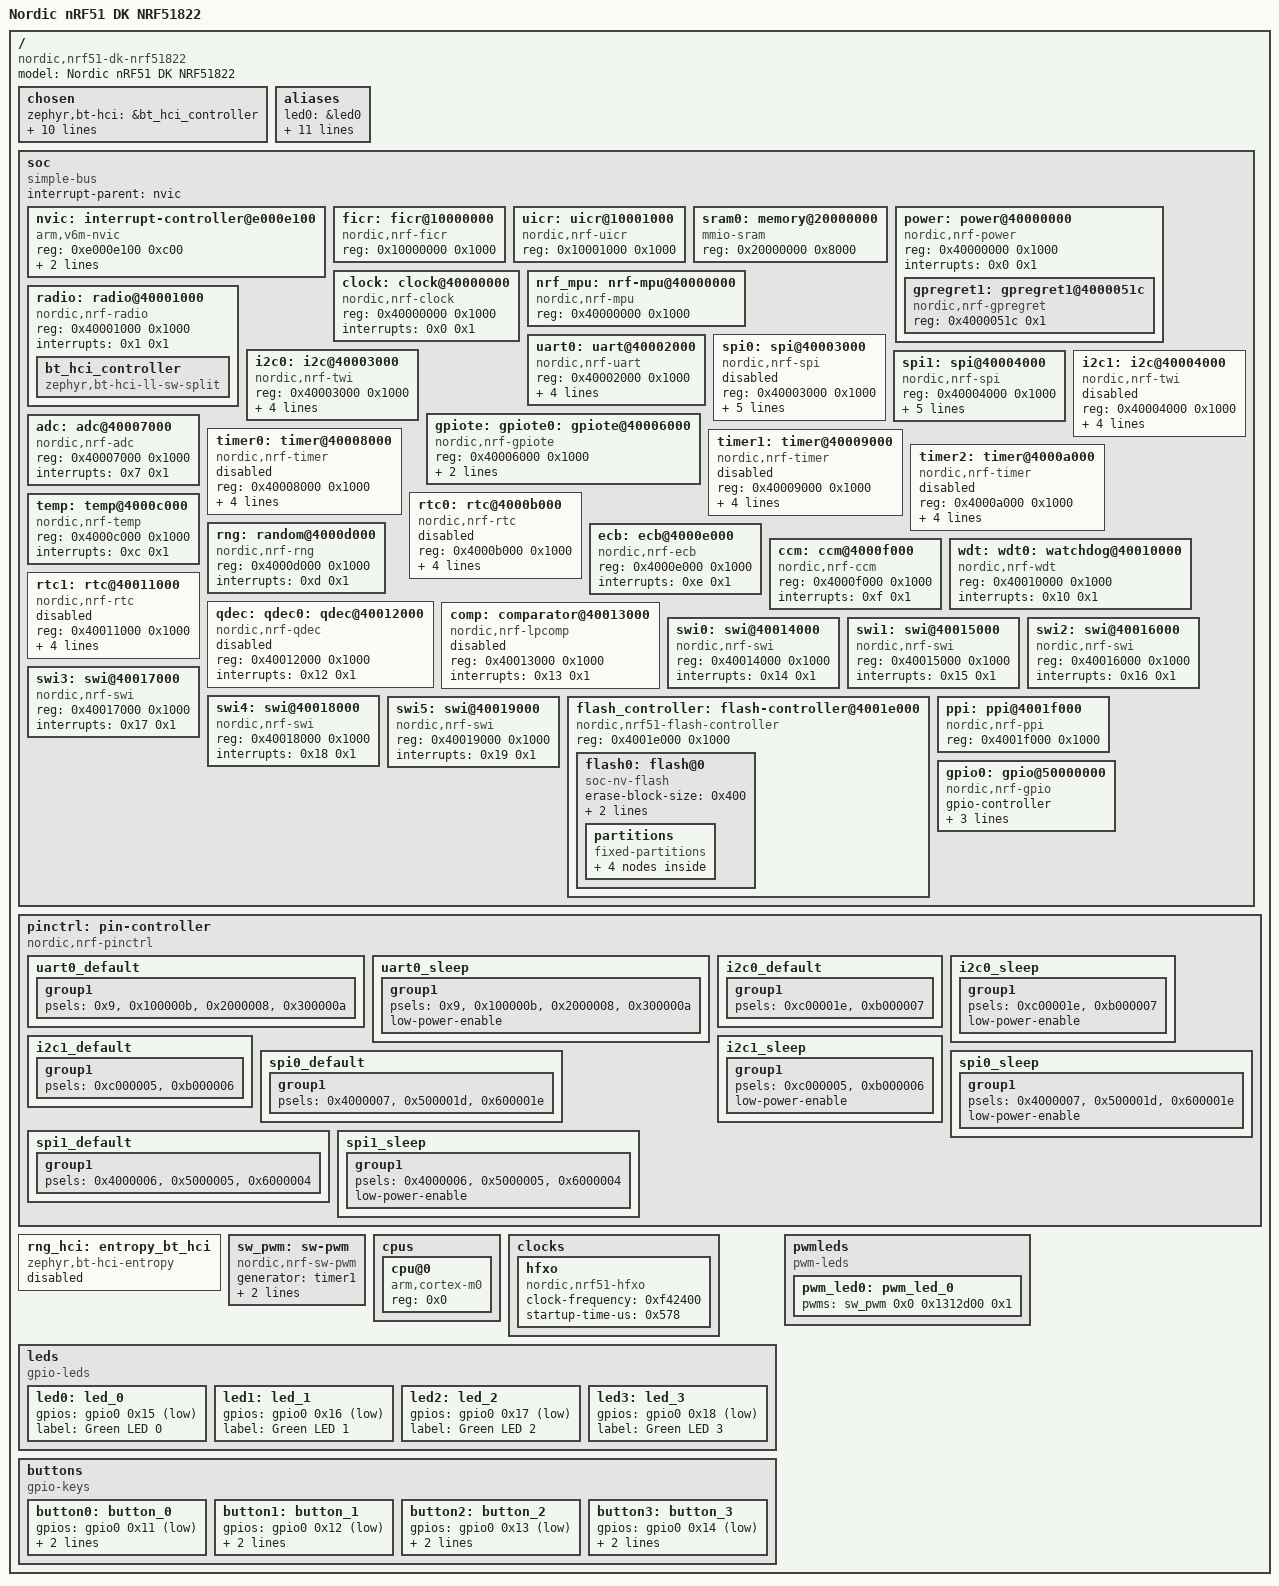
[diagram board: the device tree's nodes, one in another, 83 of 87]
/dts-v1/;

/* node '/' defined in zephyr/dts/common/skeleton.dtsi:9 */
/ {
	#address-cells = < 0x1 >;                /* in zephyr/dts/common/skeleton.dtsi:10 */
	#size-cells = < 0x1 >;                   /* in zephyr/dts/common/skeleton.dtsi:11 */
	model = "Nordic nRF51 DK NRF51822";      /* in zephyr/boards/nordic/nrf51dk/nrf51dk_nrf51822.dts:13 */
	compatible = "nordic,nrf51-dk-nrf51822"; /* in zephyr/boards/nordic/nrf51dk/nrf51dk_nrf51822.dts:14 */

	/* node '/chosen' defined in zephyr/dts/common/skeleton.dtsi:13 */
	chosen {
		zephyr,bt-hci = &bt_hci_controller;          /* in zephyr/dts/arm/nordic/nrf51822.dtsi:9 */
		zephyr,entropy = &rng;                       /* in zephyr/dts/arm/nordic/nrf51822.dtsi:10 */
		zephyr,flash-controller = &flash_controller; /* in zephyr/dts/arm/nordic/nrf51822.dtsi:11 */
		zephyr,console = &uart0;                     /* in zephyr/boards/nordic/nrf51dk/nrf51dk_nrf51822.dts:17 */
		zephyr,shell-uart = &uart0;                  /* in zephyr/boards/nordic/nrf51dk/nrf51dk_nrf51822.dts:18 */
		zephyr,uart-mcumgr = &uart0;                 /* in zephyr/boards/nordic/nrf51dk/nrf51dk_nrf51822.dts:19 */
		zephyr,bt-mon-uart = &uart0;                 /* in zephyr/boards/nordic/nrf51dk/nrf51dk_nrf51822.dts:20 */
		zephyr,bt-c2h-uart = &uart0;                 /* in zephyr/boards/nordic/nrf51dk/nrf51dk_nrf51822.dts:21 */
		zephyr,sram = &sram0;                        /* in zephyr/boards/nordic/nrf51dk/nrf51dk_nrf51822.dts:22 */
		zephyr,flash = &flash0;                      /* in zephyr/boards/nordic/nrf51dk/nrf51dk_nrf51822.dts:23 */
		zephyr,code-partition = &slot0_partition;    /* in zephyr/boards/nordic/nrf51dk/nrf51dk_nrf51822.dts:24 */
	};

	/* node '/aliases' defined in zephyr/dts/common/skeleton.dtsi:15 */
	aliases {
		led0 = &led0;               /* in zephyr/boards/nordic/nrf51dk/nrf51dk_nrf51822.dts:89 */
		led1 = &led1;               /* in zephyr/boards/nordic/nrf51dk/nrf51dk_nrf51822.dts:90 */
		led2 = &led2;               /* in zephyr/boards/nordic/nrf51dk/nrf51dk_nrf51822.dts:91 */
		led3 = &led3;               /* in zephyr/boards/nordic/nrf51dk/nrf51dk_nrf51822.dts:92 */
		pwm-led0 = &pwm_led0;       /* in zephyr/boards/nordic/nrf51dk/nrf51dk_nrf51822.dts:93 */
		sw0 = &button0;             /* in zephyr/boards/nordic/nrf51dk/nrf51dk_nrf51822.dts:94 */
		sw1 = &button1;             /* in zephyr/boards/nordic/nrf51dk/nrf51dk_nrf51822.dts:95 */
		sw2 = &button2;             /* in zephyr/boards/nordic/nrf51dk/nrf51dk_nrf51822.dts:96 */
		sw3 = &button3;             /* in zephyr/boards/nordic/nrf51dk/nrf51dk_nrf51822.dts:97 */
		mcuboot-button0 = &button0; /* in zephyr/boards/nordic/nrf51dk/nrf51dk_nrf51822.dts:98 */
		mcuboot-led0 = &led0;       /* in zephyr/boards/nordic/nrf51dk/nrf51dk_nrf51822.dts:99 */
		watchdog0 = &wdt0;          /* in zephyr/boards/nordic/nrf51dk/nrf51dk_nrf51822.dts:100 */
	};

	/* node '/soc' defined in zephyr/dts/arm/armv6-m.dtsi:6 */
	soc {
		#address-cells = < 0x1 >;     /* in zephyr/dts/arm/armv6-m.dtsi:7 */
		#size-cells = < 0x1 >;        /* in zephyr/dts/arm/armv6-m.dtsi:8 */
		interrupt-parent = < &nvic >; /* in zephyr/dts/arm/armv6-m.dtsi:10 */
		ranges;                       /* in zephyr/dts/arm/armv6-m.dtsi:11 */
		compatible = "simple-bus";    /* in zephyr/dts/arm/nordic/nrf51822_qfac.dtsi:21 */

		/* node '/soc/interrupt-controller@e000e100' defined in zephyr/dts/arm/armv6-m.dtsi:13 */
		nvic: interrupt-controller@e000e100 {
			#address-cells = < 0x1 >;            /* in zephyr/dts/arm/armv6-m.dtsi:14 */
			compatible = "arm,v6m-nvic";         /* in zephyr/dts/arm/armv6-m.dtsi:15 */
			reg = < 0xe000e100 0xc00 >;          /* in zephyr/dts/arm/armv6-m.dtsi:16 */
			interrupt-controller;                /* in zephyr/dts/arm/armv6-m.dtsi:17 */
			#interrupt-cells = < 0x2 >;          /* in zephyr/dts/arm/armv6-m.dtsi:18 */
			arm,num-irq-priority-bits = < 0x2 >; /* in zephyr/dts/arm/nordic/nrf51822.dtsi:342 */
			phandle = < 0x1 >;                   /* in zephyr/dts/arm/armv6-m.dtsi:10 */
		};

		/* node '/soc/ficr@10000000' defined in zephyr/dts/arm/nordic/nrf51822.dtsi:35 */
		ficr: ficr@10000000 {
			compatible = "nordic,nrf-ficr"; /* in zephyr/dts/arm/nordic/nrf51822.dtsi:36 */
			reg = < 0x10000000 0x1000 >;    /* in zephyr/dts/arm/nordic/nrf51822.dtsi:37 */
			#nordic,ficr-cells = < 0x1 >;   /* in zephyr/dts/arm/nordic/nrf51822.dtsi:38 */
			status = "okay";                /* in zephyr/dts/arm/nordic/nrf51822.dtsi:39 */
		};

		/* node '/soc/uicr@10001000' defined in zephyr/dts/arm/nordic/nrf51822.dtsi:42 */
		uicr: uicr@10001000 {
			compatible = "nordic,nrf-uicr"; /* in zephyr/dts/arm/nordic/nrf51822.dtsi:43 */
			reg = < 0x10001000 0x1000 >;    /* in zephyr/dts/arm/nordic/nrf51822.dtsi:44 */
			status = "okay";                /* in zephyr/dts/arm/nordic/nrf51822.dtsi:45 */
		};

		/* node '/soc/memory@20000000' defined in zephyr/dts/arm/nordic/nrf51822.dtsi:48 */
		sram0: memory@20000000 {
			compatible = "mmio-sram";           /* in zephyr/dts/arm/nordic/nrf51822.dtsi:49 */
			#address-cells = < 0x1 >;           /* in zephyr/dts/arm/nordic/nrf51822.dtsi:50 */
			#size-cells = < 0x1 >;              /* in zephyr/dts/arm/nordic/nrf51822.dtsi:51 */
			reg = < 0x20000000 0x8000 >;        /* in zephyr/dts/arm/nordic/nrf51822_qfac.dtsi:15 */
			ranges = < 0x0 0x20000000 0x8000 >; /* in zephyr/dts/arm/nordic/nrf51822_qfac.dtsi:16 */
		};

		/* node '/soc/power@40000000' defined in zephyr/dts/arm/nordic/nrf51822.dtsi:54 */
		power: power@40000000 {
			compatible = "nordic,nrf-power"; /* in zephyr/dts/arm/nordic/nrf51822.dtsi:55 */
			reg = < 0x40000000 0x1000 >;     /* in zephyr/dts/arm/nordic/nrf51822.dtsi:56 */
			interrupts = < 0x0 0x1 >;        /* in zephyr/dts/arm/nordic/nrf51822.dtsi:57 */
			status = "okay";                 /* in zephyr/dts/arm/nordic/nrf51822.dtsi:58 */
			#address-cells = < 0x1 >;        /* in zephyr/dts/arm/nordic/nrf51822.dtsi:59 */
			#size-cells = < 0x1 >;           /* in zephyr/dts/arm/nordic/nrf51822.dtsi:60 */

			/* node '/soc/power@40000000/gpregret1@4000051c' defined in zephyr/dts/arm/nordic/nrf51822.dtsi:62 */
			gpregret1: gpregret1@4000051c {
				#address-cells = < 0x1 >;           /* in zephyr/dts/arm/nordic/nrf51822.dtsi:63 */
				#size-cells = < 0x1 >;              /* in zephyr/dts/arm/nordic/nrf51822.dtsi:64 */
				compatible = "nordic,nrf-gpregret"; /* in zephyr/dts/arm/nordic/nrf51822.dtsi:65 */
				reg = < 0x4000051c 0x1 >;           /* in zephyr/dts/arm/nordic/nrf51822.dtsi:66 */
				status = "okay";                    /* in zephyr/dts/arm/nordic/nrf51822.dtsi:67 */
			};
		};

		/* node '/soc/clock@40000000' defined in zephyr/dts/arm/nordic/nrf51822.dtsi:71 */
		clock: clock@40000000 {
			compatible = "nordic,nrf-clock"; /* in zephyr/dts/arm/nordic/nrf51822.dtsi:72 */
			reg = < 0x40000000 0x1000 >;     /* in zephyr/dts/arm/nordic/nrf51822.dtsi:73 */
			interrupts = < 0x0 0x1 >;        /* in zephyr/dts/arm/nordic/nrf51822.dtsi:74 */
			status = "okay";                 /* in zephyr/dts/arm/nordic/nrf51822.dtsi:75 */
		};

		/* node '/soc/nrf-mpu@40000000' defined in zephyr/dts/arm/nordic/nrf51822.dtsi:78 */
		nrf_mpu: nrf-mpu@40000000 {
			compatible = "nordic,nrf-mpu"; /* in zephyr/dts/arm/nordic/nrf51822.dtsi:79 */
			reg = < 0x40000000 0x1000 >;   /* in zephyr/dts/arm/nordic/nrf51822.dtsi:80 */
			status = "okay";               /* in zephyr/dts/arm/nordic/nrf51822.dtsi:81 */
		};

		/* node '/soc/radio@40001000' defined in zephyr/dts/arm/nordic/nrf51822.dtsi:84 */
		radio: radio@40001000 {
			compatible = "nordic,nrf-radio"; /* in zephyr/dts/arm/nordic/nrf51822.dtsi:85 */
			reg = < 0x40001000 0x1000 >;     /* in zephyr/dts/arm/nordic/nrf51822.dtsi:86 */
			interrupts = < 0x1 0x1 >;        /* in zephyr/dts/arm/nordic/nrf51822.dtsi:87 */
			status = "okay";                 /* in zephyr/dts/arm/nordic/nrf51822.dtsi:88 */

			/* node '/soc/radio@40001000/bt_hci_controller' defined in zephyr/dts/arm/nordic/nrf51822.dtsi:90 */
			bt_hci_controller: bt_hci_controller {
				compatible = "zephyr,bt-hci-ll-sw-split"; /* in zephyr/dts/arm/nordic/nrf51822.dtsi:91 */
				status = "okay";                          /* in zephyr/dts/arm/nordic/nrf51822.dtsi:92 */
			};
		};

		/* node '/soc/uart@40002000' defined in zephyr/dts/arm/nordic/nrf51822.dtsi:96 */
		uart0: uart@40002000 {
			compatible = "nordic,nrf-uart"; /* in zephyr/dts/arm/nordic/nrf51822.dtsi:97 */
			reg = < 0x40002000 0x1000 >;    /* in zephyr/dts/arm/nordic/nrf51822.dtsi:98 */
			interrupts = < 0x2 0x1 >;       /* in zephyr/dts/arm/nordic/nrf51822.dtsi:99 */
			current-speed = < 0x1c200 >;    /* in zephyr/boards/nordic/nrf51dk/nrf51dk_nrf51822.dts:123 */
			status = "okay";                /* in zephyr/boards/nordic/nrf51dk/nrf51dk_nrf51822.dts:124 */
			pinctrl-0 = < &uart0_default >; /* in zephyr/boards/nordic/nrf51dk/nrf51dk_nrf51822.dts:125 */
			pinctrl-1 = < &uart0_sleep >;   /* in zephyr/boards/nordic/nrf51dk/nrf51dk_nrf51822.dts:126 */
			pinctrl-names = "default",
			                "sleep";        /* in zephyr/boards/nordic/nrf51dk/nrf51dk_nrf51822.dts:127 */
		};

		/* node '/soc/spi@40003000' defined in zephyr/dts/arm/nordic/nrf51822.dtsi:103 */
		spi0: spi@40003000 {
			compatible = "nordic,nrf-spi"; /* in zephyr/dts/arm/nordic/nrf51822.dtsi:104 */
			#address-cells = < 0x1 >;      /* in zephyr/dts/arm/nordic/nrf51822.dtsi:105 */
			#size-cells = < 0x0 >;         /* in zephyr/dts/arm/nordic/nrf51822.dtsi:106 */
			reg = < 0x40003000 0x1000 >;   /* in zephyr/dts/arm/nordic/nrf51822.dtsi:107 */
			interrupts = < 0x3 0x1 >;      /* in zephyr/dts/arm/nordic/nrf51822.dtsi:108 */
			max-frequency = < 0x7a1200 >;  /* in zephyr/dts/arm/nordic/nrf51822.dtsi:109 */
			easydma-maxcnt-bits = < 0x8 >; /* in zephyr/dts/arm/nordic/nrf51822.dtsi:110 */
			status = "disabled";           /* in zephyr/dts/arm/nordic/nrf51822.dtsi:111 */
			pinctrl-0 = < &spi0_default >; /* in zephyr/boards/nordic/nrf51dk/nrf51dk_nrf51822.dts:148 */
			pinctrl-1 = < &spi0_sleep >;   /* in zephyr/boards/nordic/nrf51dk/nrf51dk_nrf51822.dts:149 */
			pinctrl-names = "default",
			                "sleep";       /* in zephyr/boards/nordic/nrf51dk/nrf51dk_nrf51822.dts:150 */
		};

		/* node '/soc/i2c@40003000' defined in zephyr/dts/arm/nordic/nrf51822.dtsi:114 */
		i2c0: i2c@40003000 {
			compatible = "nordic,nrf-twi"; /* in zephyr/dts/arm/nordic/nrf51822.dtsi:115 */
			#address-cells = < 0x1 >;      /* in zephyr/dts/arm/nordic/nrf51822.dtsi:116 */
			#size-cells = < 0x0 >;         /* in zephyr/dts/arm/nordic/nrf51822.dtsi:117 */
			reg = < 0x40003000 0x1000 >;   /* in zephyr/dts/arm/nordic/nrf51822.dtsi:118 */
			interrupts = < 0x3 0x1 >;      /* in zephyr/dts/arm/nordic/nrf51822.dtsi:119 */
			easydma-maxcnt-bits = < 0x8 >; /* in zephyr/dts/arm/nordic/nrf51822.dtsi:120 */
			status = "okay";               /* in zephyr/boards/nordic/nrf51dk/nrf51dk_nrf51822.dts:131 */
			pinctrl-0 = < &i2c0_default >; /* in zephyr/boards/nordic/nrf51dk/nrf51dk_nrf51822.dts:132 */
			pinctrl-1 = < &i2c0_sleep >;   /* in zephyr/boards/nordic/nrf51dk/nrf51dk_nrf51822.dts:133 */
			pinctrl-names = "default",
			                "sleep";       /* in zephyr/boards/nordic/nrf51dk/nrf51dk_nrf51822.dts:134 */
		};

		/* node '/soc/spi@40004000' defined in zephyr/dts/arm/nordic/nrf51822.dtsi:124 */
		spi1: spi@40004000 {
			#address-cells = < 0x1 >;      /* in zephyr/dts/arm/nordic/nrf51822.dtsi:132 */
			#size-cells = < 0x0 >;         /* in zephyr/dts/arm/nordic/nrf51822.dtsi:133 */
			reg = < 0x40004000 0x1000 >;   /* in zephyr/dts/arm/nordic/nrf51822.dtsi:134 */
			interrupts = < 0x4 0x1 >;      /* in zephyr/dts/arm/nordic/nrf51822.dtsi:135 */
			max-frequency = < 0x7a1200 >;  /* in zephyr/dts/arm/nordic/nrf51822.dtsi:136 */
			easydma-maxcnt-bits = < 0x8 >; /* in zephyr/dts/arm/nordic/nrf51822.dtsi:137 */
			compatible = "nordic,nrf-spi"; /* in zephyr/boards/nordic/nrf51dk/nrf51dk_nrf51822.dts:154 */
			status = "okay";               /* in zephyr/boards/nordic/nrf51dk/nrf51dk_nrf51822.dts:155 */
			pinctrl-0 = < &spi1_default >; /* in zephyr/boards/nordic/nrf51dk/nrf51dk_nrf51822.dts:156 */
			pinctrl-1 = < &spi1_sleep >;   /* in zephyr/boards/nordic/nrf51dk/nrf51dk_nrf51822.dts:157 */
			pinctrl-names = "default",
			                "sleep";       /* in zephyr/boards/nordic/nrf51dk/nrf51dk_nrf51822.dts:158 */
		};

		/* node '/soc/i2c@40004000' defined in zephyr/dts/arm/nordic/nrf51822.dtsi:141 */
		i2c1: i2c@40004000 {
			compatible = "nordic,nrf-twi"; /* in zephyr/dts/arm/nordic/nrf51822.dtsi:142 */
			#address-cells = < 0x1 >;      /* in zephyr/dts/arm/nordic/nrf51822.dtsi:143 */
			#size-cells = < 0x0 >;         /* in zephyr/dts/arm/nordic/nrf51822.dtsi:144 */
			reg = < 0x40004000 0x1000 >;   /* in zephyr/dts/arm/nordic/nrf51822.dtsi:145 */
			interrupts = < 0x4 0x1 >;      /* in zephyr/dts/arm/nordic/nrf51822.dtsi:146 */
			easydma-maxcnt-bits = < 0x8 >; /* in zephyr/dts/arm/nordic/nrf51822.dtsi:147 */
			status = "disabled";           /* in zephyr/dts/arm/nordic/nrf51822.dtsi:148 */
			pinctrl-0 = < &i2c1_default >; /* in zephyr/boards/nordic/nrf51dk/nrf51dk_nrf51822.dts:140 */
			pinctrl-1 = < &i2c1_sleep >;   /* in zephyr/boards/nordic/nrf51dk/nrf51dk_nrf51822.dts:141 */
			pinctrl-names = "default",
			                "sleep";       /* in zephyr/boards/nordic/nrf51dk/nrf51dk_nrf51822.dts:142 */
		};

		/* node '/soc/gpiote@40006000' defined in zephyr/dts/arm/nordic/nrf51822.dtsi:151 */
		gpiote: gpiote0: gpiote@40006000 {
			compatible = "nordic,nrf-gpiote"; /* in zephyr/dts/arm/nordic/nrf51822.dtsi:152 */
			reg = < 0x40006000 0x1000 >;      /* in zephyr/dts/arm/nordic/nrf51822.dtsi:153 */
			interrupts = < 0x6 0x1 >;         /* in zephyr/dts/arm/nordic/nrf51822.dtsi:154 */
			instance = < 0x0 >;               /* in zephyr/dts/arm/nordic/nrf51822.dtsi:156 */
			status = "okay";                  /* in zephyr/boards/nordic/nrf51dk/nrf51dk_nrf51822.dts:111 */
			phandle = < 0xc >;                /* in zephyr/dts/arm/nordic/nrf51822.dtsi:336 */
		};

		/* node '/soc/adc@40007000' defined in zephyr/dts/arm/nordic/nrf51822.dtsi:159 */
		adc: adc@40007000 {
			compatible = "nordic,nrf-adc"; /* in zephyr/dts/arm/nordic/nrf51822.dtsi:160 */
			reg = < 0x40007000 0x1000 >;   /* in zephyr/dts/arm/nordic/nrf51822.dtsi:161 */
			interrupts = < 0x7 0x1 >;      /* in zephyr/dts/arm/nordic/nrf51822.dtsi:162 */
			#io-channel-cells = < 0x1 >;   /* in zephyr/dts/arm/nordic/nrf51822.dtsi:164 */
			status = "okay";               /* in zephyr/boards/nordic/nrf51dk/nrf51dk_nrf51822.dts:119 */
		};

		/* node '/soc/timer@40008000' defined in zephyr/dts/arm/nordic/nrf51822.dtsi:167 */
		timer0: timer@40008000 {
			compatible = "nordic,nrf-timer"; /* in zephyr/dts/arm/nordic/nrf51822.dtsi:168 */
			status = "disabled";             /* in zephyr/dts/arm/nordic/nrf51822.dtsi:169 */
			reg = < 0x40008000 0x1000 >;     /* in zephyr/dts/arm/nordic/nrf51822.dtsi:170 */
			cc-num = < 0x4 >;                /* in zephyr/dts/arm/nordic/nrf51822.dtsi:171 */
			max-bit-width = < 0x20 >;        /* in zephyr/dts/arm/nordic/nrf51822.dtsi:172 */
			interrupts = < 0x8 0x1 >;        /* in zephyr/dts/arm/nordic/nrf51822.dtsi:173 */
			prescaler = < 0x0 >;             /* in zephyr/dts/arm/nordic/nrf51822.dtsi:174 */
		};

		/* node '/soc/timer@40009000' defined in zephyr/dts/arm/nordic/nrf51822.dtsi:177 */
		timer1: timer@40009000 {
			compatible = "nordic,nrf-timer"; /* in zephyr/dts/arm/nordic/nrf51822.dtsi:178 */
			status = "disabled";             /* in zephyr/dts/arm/nordic/nrf51822.dtsi:179 */
			reg = < 0x40009000 0x1000 >;     /* in zephyr/dts/arm/nordic/nrf51822.dtsi:180 */
			cc-num = < 0x4 >;                /* in zephyr/dts/arm/nordic/nrf51822.dtsi:181 */
			max-bit-width = < 0x10 >;        /* in zephyr/dts/arm/nordic/nrf51822.dtsi:182 */
			interrupts = < 0x9 0x1 >;        /* in zephyr/dts/arm/nordic/nrf51822.dtsi:183 */
			prescaler = < 0x0 >;             /* in zephyr/dts/arm/nordic/nrf51822.dtsi:184 */
			phandle = < 0xd >;               /* in zephyr/dts/vendor/nordic/nrf_common.dtsi:42 */
		};

		/* node '/soc/timer@4000a000' defined in zephyr/dts/arm/nordic/nrf51822.dtsi:187 */
		timer2: timer@4000a000 {
			compatible = "nordic,nrf-timer"; /* in zephyr/dts/arm/nordic/nrf51822.dtsi:188 */
			status = "disabled";             /* in zephyr/dts/arm/nordic/nrf51822.dtsi:189 */
			reg = < 0x4000a000 0x1000 >;     /* in zephyr/dts/arm/nordic/nrf51822.dtsi:190 */
			cc-num = < 0x4 >;                /* in zephyr/dts/arm/nordic/nrf51822.dtsi:191 */
			max-bit-width = < 0x10 >;        /* in zephyr/dts/arm/nordic/nrf51822.dtsi:192 */
			interrupts = < 0xa 0x1 >;        /* in zephyr/dts/arm/nordic/nrf51822.dtsi:193 */
			prescaler = < 0x0 >;             /* in zephyr/dts/arm/nordic/nrf51822.dtsi:194 */
		};

		/* node '/soc/rtc@4000b000' defined in zephyr/dts/arm/nordic/nrf51822.dtsi:197 */
		rtc0: rtc@4000b000 {
			compatible = "nordic,nrf-rtc"; /* in zephyr/dts/arm/nordic/nrf51822.dtsi:198 */
			reg = < 0x4000b000 0x1000 >;   /* in zephyr/dts/arm/nordic/nrf51822.dtsi:199 */
			cc-num = < 0x3 >;              /* in zephyr/dts/arm/nordic/nrf51822.dtsi:200 */
			interrupts = < 0xb 0x1 >;      /* in zephyr/dts/arm/nordic/nrf51822.dtsi:201 */
			status = "disabled";           /* in zephyr/dts/arm/nordic/nrf51822.dtsi:202 */
			clock-frequency = < 0x8000 >;  /* in zephyr/dts/arm/nordic/nrf51822.dtsi:203 */
			prescaler = < 0x1 >;           /* in zephyr/dts/arm/nordic/nrf51822.dtsi:204 */
		};

		/* node '/soc/temp@4000c000' defined in zephyr/dts/arm/nordic/nrf51822.dtsi:207 */
		temp: temp@4000c000 {
			compatible = "nordic,nrf-temp"; /* in zephyr/dts/arm/nordic/nrf51822.dtsi:208 */
			reg = < 0x4000c000 0x1000 >;    /* in zephyr/dts/arm/nordic/nrf51822.dtsi:209 */
			interrupts = < 0xc 0x1 >;       /* in zephyr/dts/arm/nordic/nrf51822.dtsi:210 */
			status = "okay";                /* in zephyr/dts/arm/nordic/nrf51822.dtsi:211 */
		};

		/* node '/soc/random@4000d000' defined in zephyr/dts/arm/nordic/nrf51822.dtsi:214 */
		rng: random@4000d000 {
			compatible = "nordic,nrf-rng"; /* in zephyr/dts/arm/nordic/nrf51822.dtsi:215 */
			reg = < 0x4000d000 0x1000 >;   /* in zephyr/dts/arm/nordic/nrf51822.dtsi:216 */
			interrupts = < 0xd 0x1 >;      /* in zephyr/dts/arm/nordic/nrf51822.dtsi:217 */
			status = "okay";               /* in zephyr/dts/arm/nordic/nrf51822.dtsi:218 */
		};

		/* node '/soc/ecb@4000e000' defined in zephyr/dts/arm/nordic/nrf51822.dtsi:221 */
		ecb: ecb@4000e000 {
			compatible = "nordic,nrf-ecb"; /* in zephyr/dts/arm/nordic/nrf51822.dtsi:222 */
			reg = < 0x4000e000 0x1000 >;   /* in zephyr/dts/arm/nordic/nrf51822.dtsi:223 */
			interrupts = < 0xe 0x1 >;      /* in zephyr/dts/arm/nordic/nrf51822.dtsi:224 */
			status = "okay";               /* in zephyr/dts/arm/nordic/nrf51822.dtsi:225 */
		};

		/* node '/soc/ccm@4000f000' defined in zephyr/dts/arm/nordic/nrf51822.dtsi:228 */
		ccm: ccm@4000f000 {
			compatible = "nordic,nrf-ccm"; /* in zephyr/dts/arm/nordic/nrf51822.dtsi:229 */
			reg = < 0x4000f000 0x1000 >;   /* in zephyr/dts/arm/nordic/nrf51822.dtsi:230 */
			interrupts = < 0xf 0x1 >;      /* in zephyr/dts/arm/nordic/nrf51822.dtsi:231 */
			status = "okay";               /* in zephyr/dts/arm/nordic/nrf51822.dtsi:232 */
		};

		/* node '/soc/watchdog@40010000' defined in zephyr/dts/arm/nordic/nrf51822.dtsi:235 */
		wdt: wdt0: watchdog@40010000 {
			compatible = "nordic,nrf-wdt"; /* in zephyr/dts/arm/nordic/nrf51822.dtsi:236 */
			reg = < 0x40010000 0x1000 >;   /* in zephyr/dts/arm/nordic/nrf51822.dtsi:237 */
			interrupts = < 0x10 0x1 >;     /* in zephyr/dts/arm/nordic/nrf51822.dtsi:238 */
			status = "okay";               /* in zephyr/dts/arm/nordic/nrf51822.dtsi:239 */
		};

		/* node '/soc/rtc@40011000' defined in zephyr/dts/arm/nordic/nrf51822.dtsi:242 */
		rtc1: rtc@40011000 {
			compatible = "nordic,nrf-rtc"; /* in zephyr/dts/arm/nordic/nrf51822.dtsi:243 */
			reg = < 0x40011000 0x1000 >;   /* in zephyr/dts/arm/nordic/nrf51822.dtsi:244 */
			cc-num = < 0x4 >;              /* in zephyr/dts/arm/nordic/nrf51822.dtsi:245 */
			interrupts = < 0x11 0x1 >;     /* in zephyr/dts/arm/nordic/nrf51822.dtsi:246 */
			status = "disabled";           /* in zephyr/dts/arm/nordic/nrf51822.dtsi:247 */
			clock-frequency = < 0x8000 >;  /* in zephyr/dts/arm/nordic/nrf51822.dtsi:248 */
			prescaler = < 0x1 >;           /* in zephyr/dts/arm/nordic/nrf51822.dtsi:249 */
		};

		/* node '/soc/qdec@40012000' defined in zephyr/dts/arm/nordic/nrf51822.dtsi:252 */
		qdec: qdec0: qdec@40012000 {
			compatible = "nordic,nrf-qdec"; /* in zephyr/dts/arm/nordic/nrf51822.dtsi:253 */
			reg = < 0x40012000 0x1000 >;    /* in zephyr/dts/arm/nordic/nrf51822.dtsi:254 */
			interrupts = < 0x12 0x1 >;      /* in zephyr/dts/arm/nordic/nrf51822.dtsi:255 */
			status = "disabled";            /* in zephyr/dts/arm/nordic/nrf51822.dtsi:256 */
		};

		/* node '/soc/comparator@40013000' defined in zephyr/dts/arm/nordic/nrf51822.dtsi:259 */
		comp: comparator@40013000 {
			compatible = "nordic,nrf-lpcomp"; /* in zephyr/dts/arm/nordic/nrf51822.dtsi:260 */
			reg = < 0x40013000 0x1000 >;      /* in zephyr/dts/arm/nordic/nrf51822.dtsi:261 */
			interrupts = < 0x13 0x1 >;        /* in zephyr/dts/arm/nordic/nrf51822.dtsi:262 */
			status = "disabled";              /* in zephyr/dts/arm/nordic/nrf51822.dtsi:263 */
			#io-channel-cells = < 0x1 >;      /* in zephyr/dts/arm/nordic/nrf51822.dtsi:264 */
		};

		/* node '/soc/swi@40014000' defined in zephyr/dts/arm/nordic/nrf51822.dtsi:267 */
		swi0: swi@40014000 {
			compatible = "nordic,nrf-swi"; /* in zephyr/dts/arm/nordic/nrf51822.dtsi:268 */
			reg = < 0x40014000 0x1000 >;   /* in zephyr/dts/arm/nordic/nrf51822.dtsi:269 */
			interrupts = < 0x14 0x1 >;     /* in zephyr/dts/arm/nordic/nrf51822.dtsi:270 */
			status = "okay";               /* in zephyr/dts/arm/nordic/nrf51822.dtsi:271 */
		};

		/* node '/soc/swi@40015000' defined in zephyr/dts/arm/nordic/nrf51822.dtsi:274 */
		swi1: swi@40015000 {
			compatible = "nordic,nrf-swi"; /* in zephyr/dts/arm/nordic/nrf51822.dtsi:275 */
			reg = < 0x40015000 0x1000 >;   /* in zephyr/dts/arm/nordic/nrf51822.dtsi:276 */
			interrupts = < 0x15 0x1 >;     /* in zephyr/dts/arm/nordic/nrf51822.dtsi:277 */
			status = "okay";               /* in zephyr/dts/arm/nordic/nrf51822.dtsi:278 */
		};

		/* node '/soc/swi@40016000' defined in zephyr/dts/arm/nordic/nrf51822.dtsi:281 */
		swi2: swi@40016000 {
			compatible = "nordic,nrf-swi"; /* in zephyr/dts/arm/nordic/nrf51822.dtsi:282 */
			reg = < 0x40016000 0x1000 >;   /* in zephyr/dts/arm/nordic/nrf51822.dtsi:283 */
			interrupts = < 0x16 0x1 >;     /* in zephyr/dts/arm/nordic/nrf51822.dtsi:284 */
			status = "okay";               /* in zephyr/dts/arm/nordic/nrf51822.dtsi:285 */
		};

		/* node '/soc/swi@40017000' defined in zephyr/dts/arm/nordic/nrf51822.dtsi:288 */
		swi3: swi@40017000 {
			compatible = "nordic,nrf-swi"; /* in zephyr/dts/arm/nordic/nrf51822.dtsi:289 */
			reg = < 0x40017000 0x1000 >;   /* in zephyr/dts/arm/nordic/nrf51822.dtsi:290 */
			interrupts = < 0x17 0x1 >;     /* in zephyr/dts/arm/nordic/nrf51822.dtsi:291 */
			status = "okay";               /* in zephyr/dts/arm/nordic/nrf51822.dtsi:292 */
		};

		/* node '/soc/swi@40018000' defined in zephyr/dts/arm/nordic/nrf51822.dtsi:295 */
		swi4: swi@40018000 {
			compatible = "nordic,nrf-swi"; /* in zephyr/dts/arm/nordic/nrf51822.dtsi:296 */
			reg = < 0x40018000 0x1000 >;   /* in zephyr/dts/arm/nordic/nrf51822.dtsi:297 */
			interrupts = < 0x18 0x1 >;     /* in zephyr/dts/arm/nordic/nrf51822.dtsi:298 */
			status = "okay";               /* in zephyr/dts/arm/nordic/nrf51822.dtsi:299 */
		};

		/* node '/soc/swi@40019000' defined in zephyr/dts/arm/nordic/nrf51822.dtsi:302 */
		swi5: swi@40019000 {
			compatible = "nordic,nrf-swi"; /* in zephyr/dts/arm/nordic/nrf51822.dtsi:303 */
			reg = < 0x40019000 0x1000 >;   /* in zephyr/dts/arm/nordic/nrf51822.dtsi:304 */
			interrupts = < 0x19 0x1 >;     /* in zephyr/dts/arm/nordic/nrf51822.dtsi:305 */
			status = "okay";               /* in zephyr/dts/arm/nordic/nrf51822.dtsi:306 */
		};

		/* node '/soc/flash-controller@4001e000' defined in zephyr/dts/arm/nordic/nrf51822.dtsi:309 */
		flash_controller: flash-controller@4001e000 {
			compatible = "nordic,nrf51-flash-controller"; /* in zephyr/dts/arm/nordic/nrf51822.dtsi:310 */
			reg = < 0x4001e000 0x1000 >;                  /* in zephyr/dts/arm/nordic/nrf51822.dtsi:311 */
			#address-cells = < 0x1 >;                     /* in zephyr/dts/arm/nordic/nrf51822.dtsi:313 */
			#size-cells = < 0x1 >;                        /* in zephyr/dts/arm/nordic/nrf51822.dtsi:314 */

			/* node '/soc/flash-controller@4001e000/flash@0' defined in zephyr/dts/arm/nordic/nrf51822.dtsi:316 */
			flash0: flash@0 {
				compatible = "soc-nv-flash";  /* in zephyr/dts/arm/nordic/nrf51822.dtsi:317 */
				erase-block-size = < 0x400 >; /* in zephyr/dts/arm/nordic/nrf51822.dtsi:318 */
				write-block-size = < 0x4 >;   /* in zephyr/dts/arm/nordic/nrf51822.dtsi:319 */
				reg = < 0x0 0x40000 >;        /* in zephyr/dts/arm/nordic/nrf51822_qfac.dtsi:11 */

				/* node '/soc/flash-controller@4001e000/flash@0/partitions' defined in zephyr/boards/nordic/nrf51dk/nrf51dk_nrf51822.dts:162 */
				partitions {
					compatible = "fixed-partitions"; /* in zephyr/boards/nordic/nrf51dk/nrf51dk_nrf51822.dts:163 */
					#address-cells = < 0x1 >;        /* in zephyr/boards/nordic/nrf51dk/nrf51dk_nrf51822.dts:164 */
					#size-cells = < 0x1 >;           /* in zephyr/boards/nordic/nrf51dk/nrf51dk_nrf51822.dts:165 */

					/* node '/soc/flash-controller@4001e000/flash@0/partitions/partition@0' defined in zephyr/boards/nordic/nrf51dk/nrf51dk_nrf51822.dts:167 */
					boot_partition: partition@0 {
						label = "mcuboot";    /* in zephyr/boards/nordic/nrf51dk/nrf51dk_nrf51822.dts:168 */
						reg = < 0x0 0x8000 >; /* in zephyr/boards/nordic/nrf51dk/nrf51dk_nrf51822.dts:169 */
					};

					/* node '/soc/flash-controller@4001e000/flash@0/partitions/partition@8000' defined in zephyr/boards/nordic/nrf51dk/nrf51dk_nrf51822.dts:172 */
					slot0_partition: partition@8000 {
						label = "image-0";        /* in zephyr/boards/nordic/nrf51dk/nrf51dk_nrf51822.dts:173 */
						reg = < 0x8000 0x1b000 >; /* in zephyr/boards/nordic/nrf51dk/nrf51dk_nrf51822.dts:174 */
					};

					/* node '/soc/flash-controller@4001e000/flash@0/partitions/partition@23000' defined in zephyr/boards/nordic/nrf51dk/nrf51dk_nrf51822.dts:177 */
					slot1_partition: partition@23000 {
						label = "image-1";         /* in zephyr/boards/nordic/nrf51dk/nrf51dk_nrf51822.dts:178 */
						reg = < 0x23000 0x1b000 >; /* in zephyr/boards/nordic/nrf51dk/nrf51dk_nrf51822.dts:179 */
					};

					/* node '/soc/flash-controller@4001e000/flash@0/partitions/partition@3e000' defined in zephyr/boards/nordic/nrf51dk/nrf51dk_nrf51822.dts:182 */
					storage_partition: partition@3e000 {
						label = "storage";        /* in zephyr/boards/nordic/nrf51dk/nrf51dk_nrf51822.dts:183 */
						reg = < 0x3e000 0x2000 >; /* in zephyr/boards/nordic/nrf51dk/nrf51dk_nrf51822.dts:184 */
					};
				};
			};
		};

		/* node '/soc/ppi@4001f000' defined in zephyr/dts/arm/nordic/nrf51822.dtsi:323 */
		ppi: ppi@4001f000 {
			compatible = "nordic,nrf-ppi"; /* in zephyr/dts/arm/nordic/nrf51822.dtsi:324 */
			reg = < 0x4001f000 0x1000 >;   /* in zephyr/dts/arm/nordic/nrf51822.dtsi:325 */
			status = "okay";               /* in zephyr/dts/arm/nordic/nrf51822.dtsi:326 */
		};

		/* node '/soc/gpio@50000000' defined in zephyr/dts/arm/nordic/nrf51822.dtsi:329 */
		gpio0: gpio@50000000 {
			compatible = "nordic,nrf-gpio"; /* in zephyr/dts/arm/nordic/nrf51822.dtsi:330 */
			gpio-controller;                /* in zephyr/dts/arm/nordic/nrf51822.dtsi:331 */
			reg = < 0x50000000 0x1000 >;    /* in zephyr/dts/arm/nordic/nrf51822.dtsi:332 */
			#gpio-cells = < 0x2 >;          /* in zephyr/dts/arm/nordic/nrf51822.dtsi:333 */
			port = < 0x0 >;                 /* in zephyr/dts/arm/nordic/nrf51822.dtsi:335 */
			gpiote-instance = < &gpiote >;  /* in zephyr/dts/arm/nordic/nrf51822.dtsi:336 */
			status = "okay";                /* in zephyr/boards/nordic/nrf51dk/nrf51dk_nrf51822.dts:115 */
			phandle = < 0xe >;              /* in zephyr/boards/nordic/nrf51dk/nrf51dk_nrf51822.dts:106 */
		};
	};

	/* node '/pin-controller' defined in zephyr/dts/vendor/nordic/nrf_common.dtsi:26 */
	pinctrl: pin-controller {
		compatible = "nordic,nrf-pinctrl"; /* in zephyr/dts/vendor/nordic/nrf_common.dtsi:31 */

		/* node '/pin-controller/uart0_default' defined in zephyr/boards/nordic/nrf51dk/nrf51dk_nrf51822-pinctrl.dtsi:7 */
		uart0_default: uart0_default {
			phandle = < 0x2 >; /* in zephyr/boards/nordic/nrf51dk/nrf51dk_nrf51822.dts:125 */

			/* node '/pin-controller/uart0_default/group1' defined in zephyr/boards/nordic/nrf51dk/nrf51dk_nrf51822-pinctrl.dtsi:8 */
			group1 {
				psels = < 0x9 >,
				        < 0x100000b >,
				        < 0x2000008 >,
				        < 0x300000a >; /* in zephyr/boards/nordic/nrf51dk/nrf51dk_nrf51822-pinctrl.dtsi:9 */
			};
		};

		/* node '/pin-controller/uart0_sleep' defined in zephyr/boards/nordic/nrf51dk/nrf51dk_nrf51822-pinctrl.dtsi:16 */
		uart0_sleep: uart0_sleep {
			phandle = < 0x3 >; /* in zephyr/boards/nordic/nrf51dk/nrf51dk_nrf51822.dts:126 */

			/* node '/pin-controller/uart0_sleep/group1' defined in zephyr/boards/nordic/nrf51dk/nrf51dk_nrf51822-pinctrl.dtsi:17 */
			group1 {
				psels = < 0x9 >,
				        < 0x100000b >,
				        < 0x2000008 >,
				        < 0x300000a >; /* in zephyr/boards/nordic/nrf51dk/nrf51dk_nrf51822-pinctrl.dtsi:18 */
				low-power-enable;      /* in zephyr/boards/nordic/nrf51dk/nrf51dk_nrf51822-pinctrl.dtsi:22 */
			};
		};

		/* node '/pin-controller/i2c0_default' defined in zephyr/boards/nordic/nrf51dk/nrf51dk_nrf51822-pinctrl.dtsi:26 */
		i2c0_default: i2c0_default {
			phandle = < 0x6 >; /* in zephyr/boards/nordic/nrf51dk/nrf51dk_nrf51822.dts:132 */

			/* node '/pin-controller/i2c0_default/group1' defined in zephyr/boards/nordic/nrf51dk/nrf51dk_nrf51822-pinctrl.dtsi:27 */
			group1 {
				psels = < 0xc00001e >,
				        < 0xb000007 >; /* in zephyr/boards/nordic/nrf51dk/nrf51dk_nrf51822-pinctrl.dtsi:28 */
			};
		};

		/* node '/pin-controller/i2c0_sleep' defined in zephyr/boards/nordic/nrf51dk/nrf51dk_nrf51822-pinctrl.dtsi:33 */
		i2c0_sleep: i2c0_sleep {
			phandle = < 0x7 >; /* in zephyr/boards/nordic/nrf51dk/nrf51dk_nrf51822.dts:133 */

			/* node '/pin-controller/i2c0_sleep/group1' defined in zephyr/boards/nordic/nrf51dk/nrf51dk_nrf51822-pinctrl.dtsi:34 */
			group1 {
				psels = < 0xc00001e >,
				        < 0xb000007 >; /* in zephyr/boards/nordic/nrf51dk/nrf51dk_nrf51822-pinctrl.dtsi:35 */
				low-power-enable;      /* in zephyr/boards/nordic/nrf51dk/nrf51dk_nrf51822-pinctrl.dtsi:37 */
			};
		};

		/* node '/pin-controller/i2c1_default' defined in zephyr/boards/nordic/nrf51dk/nrf51dk_nrf51822-pinctrl.dtsi:41 */
		i2c1_default: i2c1_default {
			phandle = < 0xa >; /* in zephyr/boards/nordic/nrf51dk/nrf51dk_nrf51822.dts:140 */

			/* node '/pin-controller/i2c1_default/group1' defined in zephyr/boards/nordic/nrf51dk/nrf51dk_nrf51822-pinctrl.dtsi:42 */
			group1 {
				psels = < 0xc000005 >,
				        < 0xb000006 >; /* in zephyr/boards/nordic/nrf51dk/nrf51dk_nrf51822-pinctrl.dtsi:43 */
			};
		};

		/* node '/pin-controller/i2c1_sleep' defined in zephyr/boards/nordic/nrf51dk/nrf51dk_nrf51822-pinctrl.dtsi:48 */
		i2c1_sleep: i2c1_sleep {
			phandle = < 0xb >; /* in zephyr/boards/nordic/nrf51dk/nrf51dk_nrf51822.dts:141 */

			/* node '/pin-controller/i2c1_sleep/group1' defined in zephyr/boards/nordic/nrf51dk/nrf51dk_nrf51822-pinctrl.dtsi:49 */
			group1 {
				psels = < 0xc000005 >,
				        < 0xb000006 >; /* in zephyr/boards/nordic/nrf51dk/nrf51dk_nrf51822-pinctrl.dtsi:50 */
				low-power-enable;      /* in zephyr/boards/nordic/nrf51dk/nrf51dk_nrf51822-pinctrl.dtsi:52 */
			};
		};

		/* node '/pin-controller/spi0_default' defined in zephyr/boards/nordic/nrf51dk/nrf51dk_nrf51822-pinctrl.dtsi:56 */
		spi0_default: spi0_default {
			phandle = < 0x4 >; /* in zephyr/boards/nordic/nrf51dk/nrf51dk_nrf51822.dts:148 */

			/* node '/pin-controller/spi0_default/group1' defined in zephyr/boards/nordic/nrf51dk/nrf51dk_nrf51822-pinctrl.dtsi:57 */
			group1 {
				psels = < 0x4000007 >,
				        < 0x500001d >,
				        < 0x600001e >; /* in zephyr/boards/nordic/nrf51dk/nrf51dk_nrf51822-pinctrl.dtsi:58 */
			};
		};

		/* node '/pin-controller/spi0_sleep' defined in zephyr/boards/nordic/nrf51dk/nrf51dk_nrf51822-pinctrl.dtsi:64 */
		spi0_sleep: spi0_sleep {
			phandle = < 0x5 >; /* in zephyr/boards/nordic/nrf51dk/nrf51dk_nrf51822.dts:149 */

			/* node '/pin-controller/spi0_sleep/group1' defined in zephyr/boards/nordic/nrf51dk/nrf51dk_nrf51822-pinctrl.dtsi:65 */
			group1 {
				psels = < 0x4000007 >,
				        < 0x500001d >,
				        < 0x600001e >; /* in zephyr/boards/nordic/nrf51dk/nrf51dk_nrf51822-pinctrl.dtsi:66 */
				low-power-enable;      /* in zephyr/boards/nordic/nrf51dk/nrf51dk_nrf51822-pinctrl.dtsi:69 */
			};
		};

		/* node '/pin-controller/spi1_default' defined in zephyr/boards/nordic/nrf51dk/nrf51dk_nrf51822-pinctrl.dtsi:73 */
		spi1_default: spi1_default {
			phandle = < 0x8 >; /* in zephyr/boards/nordic/nrf51dk/nrf51dk_nrf51822.dts:156 */

			/* node '/pin-controller/spi1_default/group1' defined in zephyr/boards/nordic/nrf51dk/nrf51dk_nrf51822-pinctrl.dtsi:74 */
			group1 {
				psels = < 0x4000006 >,
				        < 0x5000005 >,
				        < 0x6000004 >; /* in zephyr/boards/nordic/nrf51dk/nrf51dk_nrf51822-pinctrl.dtsi:75 */
			};
		};

		/* node '/pin-controller/spi1_sleep' defined in zephyr/boards/nordic/nrf51dk/nrf51dk_nrf51822-pinctrl.dtsi:81 */
		spi1_sleep: spi1_sleep {
			phandle = < 0x9 >; /* in zephyr/boards/nordic/nrf51dk/nrf51dk_nrf51822.dts:157 */

			/* node '/pin-controller/spi1_sleep/group1' defined in zephyr/boards/nordic/nrf51dk/nrf51dk_nrf51822-pinctrl.dtsi:82 */
			group1 {
				psels = < 0x4000006 >,
				        < 0x5000005 >,
				        < 0x6000004 >; /* in zephyr/boards/nordic/nrf51dk/nrf51dk_nrf51822-pinctrl.dtsi:83 */
				low-power-enable;      /* in zephyr/boards/nordic/nrf51dk/nrf51dk_nrf51822-pinctrl.dtsi:86 */
			};
		};
	};

	/* node '/entropy_bt_hci' defined in zephyr/dts/vendor/nordic/nrf_common.dtsi:34 */
	rng_hci: entropy_bt_hci {
		compatible = "zephyr,bt-hci-entropy"; /* in zephyr/dts/vendor/nordic/nrf_common.dtsi:35 */
		status = "disabled";                  /* in zephyr/dts/vendor/nordic/nrf_common.dtsi:36 */
	};

	/* node '/sw-pwm' defined in zephyr/dts/vendor/nordic/nrf_common.dtsi:39 */
	sw_pwm: sw-pwm {
		compatible = "nordic,nrf-sw-pwm";    /* in zephyr/dts/vendor/nordic/nrf_common.dtsi:40 */
		generator = < &timer1 >;             /* in zephyr/dts/vendor/nordic/nrf_common.dtsi:42 */
		#pwm-cells = < 0x3 >;                /* in zephyr/dts/vendor/nordic/nrf_common.dtsi:44 */
		status = "okay";                     /* in zephyr/boards/nordic/nrf51dk/nrf51dk_nrf51822.dts:105 */
		channel-gpios = < &gpio0 0x15 0x1 >; /* in zephyr/boards/nordic/nrf51dk/nrf51dk_nrf51822.dts:106 */
		clock-prescaler = < 0x8 >;           /* in zephyr/boards/nordic/nrf51dk/nrf51dk_nrf51822.dts:107 */
		phandle = < 0xf >;                   /* in zephyr/boards/nordic/nrf51dk/nrf51dk_nrf51822.dts:55 */
	};

	/* node '/cpus' defined in zephyr/dts/arm/nordic/nrf51822.dtsi:14 */
	cpus {
		#address-cells = < 0x1 >; /* in zephyr/dts/arm/nordic/nrf51822.dtsi:15 */
		#size-cells = < 0x0 >;    /* in zephyr/dts/arm/nordic/nrf51822.dtsi:16 */

		/* node '/cpus/cpu@0' defined in zephyr/dts/arm/nordic/nrf51822.dtsi:18 */
		cpu@0 {
			device_type = "cpu";          /* in zephyr/dts/arm/nordic/nrf51822.dtsi:19 */
			compatible = "arm,cortex-m0"; /* in zephyr/dts/arm/nordic/nrf51822.dtsi:20 */
			reg = < 0x0 >;                /* in zephyr/dts/arm/nordic/nrf51822.dtsi:21 */
		};
	};

	/* node '/clocks' defined in zephyr/dts/arm/nordic/nrf51822.dtsi:25 */
	clocks {

		/* node '/clocks/hfxo' defined in zephyr/dts/arm/nordic/nrf51822.dtsi:26 */
		hfxo: hfxo {
			compatible = "nordic,nrf51-hfxo"; /* in zephyr/dts/arm/nordic/nrf51822.dtsi:27 */
			clock-frequency = < 0xf42400 >;   /* in zephyr/dts/arm/nordic/nrf51822.dtsi:28 */
			startup-time-us = < 0x578 >;      /* in zephyr/dts/arm/nordic/nrf51822.dtsi:29 */
			#clock-cells = < 0x0 >;           /* in zephyr/dts/arm/nordic/nrf51822.dtsi:30 */
		};
	};

	/* node '/leds' defined in zephyr/boards/nordic/nrf51dk/nrf51dk_nrf51822.dts:27 */
	leds {
		compatible = "gpio-leds"; /* in zephyr/boards/nordic/nrf51dk/nrf51dk_nrf51822.dts:28 */

		/* node '/leds/led_0' defined in zephyr/boards/nordic/nrf51dk/nrf51dk_nrf51822.dts:30 */
		led0: led_0 {
			gpios = < &gpio0 0x15 0x1 >; /* in zephyr/boards/nordic/nrf51dk/nrf51dk_nrf51822.dts:31 */
			label = "Green LED 0";       /* in zephyr/boards/nordic/nrf51dk/nrf51dk_nrf51822.dts:32 */
		};

		/* node '/leds/led_1' defined in zephyr/boards/nordic/nrf51dk/nrf51dk_nrf51822.dts:35 */
		led1: led_1 {
			gpios = < &gpio0 0x16 0x1 >; /* in zephyr/boards/nordic/nrf51dk/nrf51dk_nrf51822.dts:36 */
			label = "Green LED 1";       /* in zephyr/boards/nordic/nrf51dk/nrf51dk_nrf51822.dts:37 */
		};

		/* node '/leds/led_2' defined in zephyr/boards/nordic/nrf51dk/nrf51dk_nrf51822.dts:40 */
		led2: led_2 {
			gpios = < &gpio0 0x17 0x1 >; /* in zephyr/boards/nordic/nrf51dk/nrf51dk_nrf51822.dts:41 */
			label = "Green LED 2";       /* in zephyr/boards/nordic/nrf51dk/nrf51dk_nrf51822.dts:42 */
		};

		/* node '/leds/led_3' defined in zephyr/boards/nordic/nrf51dk/nrf51dk_nrf51822.dts:45 */
		led3: led_3 {
			gpios = < &gpio0 0x18 0x1 >; /* in zephyr/boards/nordic/nrf51dk/nrf51dk_nrf51822.dts:46 */
			label = "Green LED 3";       /* in zephyr/boards/nordic/nrf51dk/nrf51dk_nrf51822.dts:47 */
		};
	};

	/* node '/pwmleds' defined in zephyr/boards/nordic/nrf51dk/nrf51dk_nrf51822.dts:51 */
	pwmleds {
		compatible = "pwm-leds"; /* in zephyr/boards/nordic/nrf51dk/nrf51dk_nrf51822.dts:52 */

		/* node '/pwmleds/pwm_led_0' defined in zephyr/boards/nordic/nrf51dk/nrf51dk_nrf51822.dts:54 */
		pwm_led0: pwm_led_0 {
			pwms = < &sw_pwm 0x0 0x1312d00 0x1 >; /* in zephyr/boards/nordic/nrf51dk/nrf51dk_nrf51822.dts:55 */
		};
	};

	/* node '/buttons' defined in zephyr/boards/nordic/nrf51dk/nrf51dk_nrf51822.dts:59 */
	buttons {
		compatible = "gpio-keys"; /* in zephyr/boards/nordic/nrf51dk/nrf51dk_nrf51822.dts:60 */

		/* node '/buttons/button_0' defined in zephyr/boards/nordic/nrf51dk/nrf51dk_nrf51822.dts:62 */
		button0: button_0 {
			gpios = < &gpio0 0x11 0x11 >;   /* in zephyr/boards/nordic/nrf51dk/nrf51dk_nrf51822.dts:63 */
			label = "Push button switch 0"; /* in zephyr/boards/nordic/nrf51dk/nrf51dk_nrf51822.dts:64 */
			zephyr,code = < 0xb >;          /* in zephyr/boards/nordic/nrf51dk/nrf51dk_nrf51822.dts:65 */
		};

		/* node '/buttons/button_1' defined in zephyr/boards/nordic/nrf51dk/nrf51dk_nrf51822.dts:68 */
		button1: button_1 {
			gpios = < &gpio0 0x12 0x11 >;   /* in zephyr/boards/nordic/nrf51dk/nrf51dk_nrf51822.dts:69 */
			label = "Push button switch 1"; /* in zephyr/boards/nordic/nrf51dk/nrf51dk_nrf51822.dts:70 */
			zephyr,code = < 0x2 >;          /* in zephyr/boards/nordic/nrf51dk/nrf51dk_nrf51822.dts:71 */
		};

		/* node '/buttons/button_2' defined in zephyr/boards/nordic/nrf51dk/nrf51dk_nrf51822.dts:74 */
		button2: button_2 {
			gpios = < &gpio0 0x13 0x11 >;   /* in zephyr/boards/nordic/nrf51dk/nrf51dk_nrf51822.dts:75 */
			label = "Push button switch 2"; /* in zephyr/boards/nordic/nrf51dk/nrf51dk_nrf51822.dts:76 */
			zephyr,code = < 0x3 >;          /* in zephyr/boards/nordic/nrf51dk/nrf51dk_nrf51822.dts:77 */
		};

		/* node '/buttons/button_3' defined in zephyr/boards/nordic/nrf51dk/nrf51dk_nrf51822.dts:80 */
		button3: button_3 {
			gpios = < &gpio0 0x14 0x11 >;   /* in zephyr/boards/nordic/nrf51dk/nrf51dk_nrf51822.dts:81 */
			label = "Push button switch 3"; /* in zephyr/boards/nordic/nrf51dk/nrf51dk_nrf51822.dts:82 */
			zephyr,code = < 0x4 >;          /* in zephyr/boards/nordic/nrf51dk/nrf51dk_nrf51822.dts:83 */
		};
	};
};
